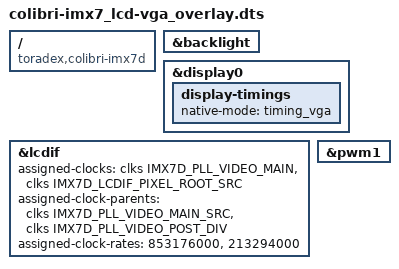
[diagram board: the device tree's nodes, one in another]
// SPDX-License-Identifier: GPL-2.0-or-later OR MIT
/*
 * Copyright 2020-2021 Toradex
 */

// Enable the parallel RGB interface with settings for VGA Displays on the Colibri iMX7
#include <dt-bindings/clock/imx7d-clock.h>

/dts-v1/;
/plugin/;

/ {
	compatible = "toradex,colibri-imx7d",
		     "toradex,colibri-imx7d-emmc",
		     "toradex,colibri-imx7s";
};

&backlight {
	status = "okay";
};

&display0 {
	display-timings {
		native-mode = <&timing_vga>;
	};
};

&lcdif {
	assigned-clocks = <&clks IMX7D_PLL_VIDEO_MAIN>,
			  <&clks IMX7D_LCDIF_PIXEL_ROOT_SRC>;
	assigned-clock-parents = <&clks IMX7D_PLL_VIDEO_MAIN_SRC>,
				 <&clks IMX7D_PLL_VIDEO_POST_DIV>;
	assigned-clock-rates = <853176000>, <213294000>;
	status = "okay";
};

&pwm1 {
	status = "okay";
};
